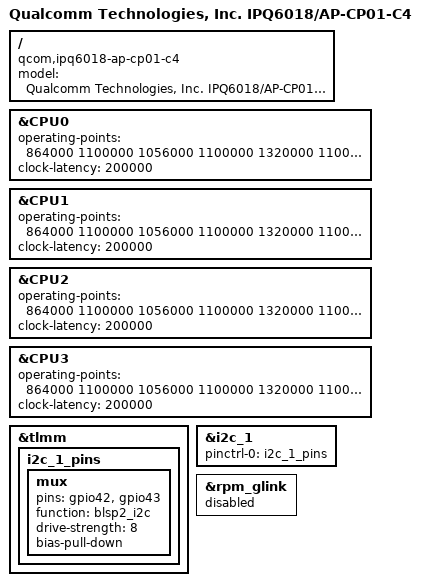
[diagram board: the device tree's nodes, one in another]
/dts-v1/;
/*
 * Copyright (c) 2020-2021, The Linux Foundation. All rights reserved.
 *
 * Permission to use, copy, modify, and/or distribute this software for any
 * purpose with or without fee is hereby granted, provided that the above
 * copyright notice and this permission notice appear in all copies.
 *
 * THE SOFTWARE IS PROVIDED "AS IS" AND THE AUTHOR DISCLAIMS ALL WARRANTIES
 * WITH REGARD TO THIS SOFTWARE INCLUDING ALL IMPLIED WARRANTIES OF
 * MERCHANTABILITY AND FITNESS. IN NO EVENT SHALL THE AUTHOR BE LIABLE FOR
 * ANY SPECIAL, DIRECT, INDIRECT, OR CONSEQUENTIAL DAMAGES OR ANY DAMAGES
 * WHATSOEVER RESULTING FROM LOSS OF USE, DATA OR PROFITS, WHETHER IN AN
 * ACTION OF CONTRACT, NEGLIGENCE OR OTHER TORTIOUS ACTION, ARISING OUT OF
 * OR IN CONNECTION WITH THE USE OR PERFORMANCE OF THIS SOFTWARE.
 */

#include "ipq6018-cp01.dtsi"

/ {
	model = "Qualcomm Technologies, Inc. IPQ6018/AP-CP01-C4";
	compatible = "qcom,ipq6018-ap-cp01-c4", "qcom,ipq6018-ap-cp01", "qcom,ipq6018";
};

&CPU0 {
	operating-points = <
		/* kHz   uV (fixed) */
		864000   1100000
		1056000  1100000
		1320000  1100000
		1440000  1100000
		1608000  1100000
		1800000  1100000
	>;
	clock-latency = <200000>;
};

&CPU1 {
	operating-points = <
		/* kHz   uV (fixed) */
		864000   1100000
		1056000  1100000
		1320000  1100000
		1440000  1100000
		1608000  1100000
		1800000  1100000
	>;
	clock-latency = <200000>;
};

&CPU2 {
	operating-points = <
		/* kHz   uV (fixed) */
		864000   1100000
		1056000  1100000
		1320000  1100000
		1440000  1100000
		1608000  1100000
		1800000  1100000
	>;
	clock-latency = <200000>;
};

&CPU3 {
	operating-points = <
		/* kHz   uV (fixed) */
		864000   1100000
		1056000  1100000
		1320000  1100000
		1440000  1100000
		1608000  1100000
		1800000  1100000
	>;
	clock-latency = <200000>;
};

&tlmm {
	i2c_1_pins: i2c_1_pins {
		mux {
			pins = "gpio42", "gpio43";
			function = "blsp2_i2c";
			drive-strength = <8>;
			bias-pull-down;
		};
	};
};

&i2c_1 {
	pinctrl-0 = <&i2c_1_pins>;
	pinctrl-names = "default";
	status = "ok";
};

&rpm_glink {
	status = "disabled";
};
